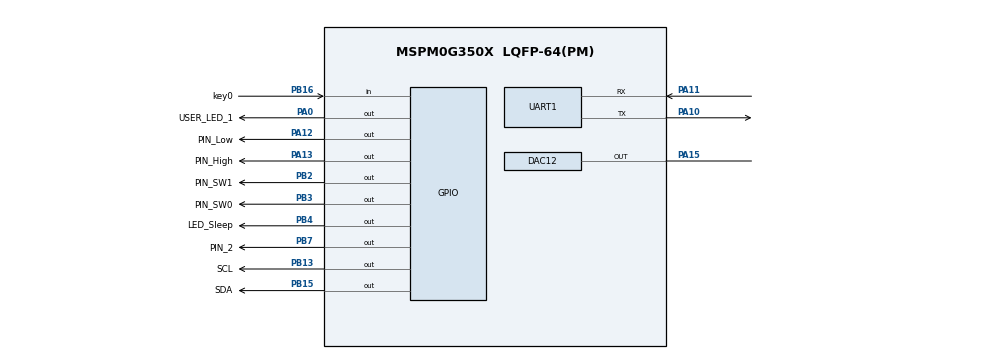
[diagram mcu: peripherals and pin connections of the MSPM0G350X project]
/**
 * @cliArgs --device "MSPM0G350X" --package "LQFP-64(PM)" --part "Default" --product "mspm0_sdk@1.30.00.03"
 * @versions {"tool":"1.20.0+3587"}
 */

/**
 * Import the modules used in this configuration.
 */
const ADC12         = scripting.addModule("/ti/driverlib/ADC12", {}, false);
const ADC121        = ADC12.addInstance();
const ADC122        = ADC12.addInstance();
const DAC12         = scripting.addModule("/ti/driverlib/DAC12");
const GPAMP         = scripting.addModule("/ti/driverlib/GPAMP", {}, false);
const GPAMP1        = GPAMP.addInstance();
const GPIO          = scripting.addModule("/ti/driverlib/GPIO", {}, false);
const GPIO1         = GPIO.addInstance();
const GPIO2         = GPIO.addInstance();
const GPIO3         = GPIO.addInstance();
const GPIO4         = GPIO.addInstance();
const GPIO5         = GPIO.addInstance();
const GPIO6         = GPIO.addInstance();
const MATHACL       = scripting.addModule("/ti/driverlib/MATHACL");
const OPA           = scripting.addModule("/ti/driverlib/OPA", {}, false);
const OPA1          = OPA.addInstance();
const OPA2          = OPA.addInstance();
const SYSCTL        = scripting.addModule("/ti/driverlib/SYSCTL");
const TIMER         = scripting.addModule("/ti/driverlib/TIMER", {}, false);
const TIMER1        = TIMER.addInstance();
const TIMER2        = TIMER.addInstance();
const UART          = scripting.addModule("/ti/driverlib/UART", {}, false);
const UART1         = UART.addInstance();
const UART2         = UART.addInstance();
const VREF          = scripting.addModule("/ti/driverlib/VREF");
const ProjectConfig = scripting.addModule("/ti/project_config/ProjectConfig");

/**
 * Write custom configuration values to the imported modules.
 */
const gate8  = system.clockTree["MFPCLKGATE"];
gate8.enable = true;

const multiplier2         = system.clockTree["PLL_QDIV"];
multiplier2.multiplyValue = 5;

ADC121.$name                 = "ADC12_0";
ADC121.adcMem0avgen          = true;
ADC121.hwNumerator           = "DL_ADC12_HW_AVG_NUM_ACC_16";
ADC121.powerDownMode         = "DL_ADC12_POWER_DOWN_MODE_MANUAL";
ADC121.samplingOperationMode = "sequence";
ADC121.endAdd                = 1;
ADC121.adcMem1avgen          = true;
ADC121.hwDenominator         = "DL_ADC12_HW_AVG_DEN_DIV_BY_16";
ADC121.sampCnt               = 2;
ADC121.repeatMode            = true;
ADC121.enabledDMATriggers    = ["DL_ADC12_DMA_MEM11_RESULT_LOADED","DL_ADC12_DMA_MEM1_RESULT_LOADED","DL_ADC12_DMA_MEM3_RESULT_LOADED","DL_ADC12_DMA_MEM5_RESULT_LOADED","DL_ADC12_DMA_MEM7_RESULT_LOADED","DL_ADC12_DMA_MEM9_RESULT_LOADED"];
ADC121.enabledInterrupts     = ["DL_ADC12_INTERRUPT_MEM1_RESULT_LOADED"];
ADC121.sampleTime0           = "62.5 ns";
ADC121.adcMem1chansel        = "DL_ADC12_INPUT_CHAN_13";
ADC121.adcMem0chansel        = "DL_ADC12_INPUT_CHAN_14";

ADC122.$name               = "ADC12_1";
ADC122.adcMem0chansel      = "DL_ADC12_INPUT_CHAN_2";
ADC122.enabledInterrupts   = ["DL_ADC12_INTERRUPT_MEM0_RESULT_LOADED"];
ADC122.adcMem0avgen        = true;
ADC122.hwNumerator         = "DL_ADC12_HW_AVG_NUM_ACC_16";
ADC122.hwDenominator       = "DL_ADC12_HW_AVG_DEN_DIV_BY_16";
ADC122.repeatMode          = true;
ADC122.sampleTime0         = "100us";
ADC122.adcPin2Config.$name = "ti_driverlib_gpio_GPIOPinGeneric8";

const Board = scripting.addModule("/ti/driverlib/Board", {}, false);

DAC12.dacFIFOEn                 = true;
DAC12.dacSampleTimerRate        = "1M";
DAC12.dacOutputPinEn            = true;
DAC12.dacConfigureDMA           = true;
DAC12.dacFIFOThresh             = "TWO_QTRS_EMPTY";
DAC12.dacAmplifier              = "ON";
DAC12.dacPosVREF                = "VEREFP";
DAC12.peripheral.OutPin.$assign = "PA15";
DAC12.OutPinConfig.$name        = "ti_driverlib_gpio_GPIOPinGeneric2";
DAC12.DMA_CHANNEL.$name         = "DMA_CH1";
DAC12.DMA_CHANNEL.srcLength     = "HALF_WORD";
DAC12.DMA_CHANNEL.dstLength     = "HALF_WORD";
DAC12.DMA_CHANNEL.addressMode   = "b2f";
DAC12.DMA_CHANNEL.transferMode  = "FULL_CH_REPEAT_SINGLE";

GPAMP1.$name                = "GPAMP_0";
GPAMP1.cfgPSELChannel       = "IN_POS";
GPAMP1.cfgNSELChannel       = "INTERNAL_OUTPUT";
GPAMP1.cfgChoppingMode      = "ADC_ASSISTED";
GPAMP1.InPosPinConfig.$name = "ti_driverlib_gpio_GPIOPinGeneric9";

GPIO1.$name                          = "GPIO_LEDS";
GPIO1.associatedPins.create(2);
GPIO1.associatedPins[0].$name        = "USER_LED_1";
GPIO1.associatedPins[0].assignedPort = "PORTA";
GPIO1.associatedPins[0].initialValue = "SET";
GPIO1.associatedPins[0].assignedPin  = "0";
GPIO1.associatedPins[0].pin.$assign  = "PA0";
GPIO1.associatedPins[1].$name        = "LED_Sleep";
GPIO1.associatedPins[1].initialValue = "SET";
GPIO1.associatedPins[1].pin.$assign  = "PB4";

GPIO2.$name                         = "GPIO_IIC";
GPIO2.port                          = "PORTB";
GPIO2.associatedPins.create(2);
GPIO2.associatedPins[0].$name       = "SCL";
GPIO2.associatedPins[0].pin.$assign = "PB13";
GPIO2.associatedPins[1].$name       = "SDA";
GPIO2.associatedPins[1].pin.$assign = "PB15";

GPIO3.$name                              = "GPIO_KEY";
GPIO3.associatedPins[0].direction        = "INPUT";
GPIO3.associatedPins[0].interruptEn      = true;
GPIO3.associatedPins[0].$name            = "key0";
GPIO3.associatedPins[0].polarity         = "RISE_FALL";
GPIO3.associatedPins[0].internalResistor = "PULL_UP";
GPIO3.associatedPins[0].pin.$assign      = "PB16";

GPIO4.$name                          = "GPIO_Relay";
GPIO4.associatedPins[0].$name        = "PIN_2";
GPIO4.associatedPins[0].initialValue = "SET";
GPIO4.associatedPins[0].pin.$assign  = "PB7";

GPIO5.$name                         = "GPIO_Measure";
GPIO5.associatedPins.create(2);
GPIO5.associatedPins[0].$name       = "PIN_High";
GPIO5.associatedPins[0].pin.$assign = "PA13";
GPIO5.associatedPins[1].$name       = "PIN_Low";
GPIO5.associatedPins[1].pin.$assign = "PA12";

GPIO6.$name                          = "GPIO_SW";
GPIO6.port                           = "PORTB";
GPIO6.associatedPins.create(2);
GPIO6.associatedPins[0].$name        = "PIN_SW1";
GPIO6.associatedPins[0].pin.$assign  = "PB2";
GPIO6.associatedPins[1].$name        = "PIN_SW0";
GPIO6.associatedPins[1].initialValue = "SET";
GPIO6.associatedPins[1].pin.$assign  = "PB3";

OPA1.$name                 = "OPA_0";
OPA1.cfg0PSELChannel       = "IN1_POS";
OPA1.cfg0NSELChannel       = "RTAP";
OPA1.advRRI                = true;
OPA1.advBW                 = "HIGH";
OPA1.cfg0Gain              = "N1_P2";
OPA1.cfg0Chop              = "ADC_AVERAGING";
OPA1.cfg0MSELChannel       = "IN1_NEG";
OPA1.peripheral.$assign    = "OPA0";
OPA1.In1PosPinConfig.$name = "ti_driverlib_gpio_GPIOPinGeneric4";
OPA1.In1NegPinConfig.$name = "ti_driverlib_gpio_GPIOPinGeneric11";

OPA2.$name                 = "OPA_1";
OPA2.cfg0PSELChannel       = "IN1_POS";
OPA2.cfg0NSELChannel       = "RTAP";
OPA2.advBW                 = "HIGH";
OPA2.advRRI                = true;
OPA2.cfg0MSELChannel       = "GND";
OPA2.cfg0OutputPin         = "ENABLED";
OPA2.cfg0Gain              = "N1_P2";
OPA2.cfg0Chop              = "STANDARD";
OPA2.In1PosPinConfig.$name = "ti_driverlib_gpio_GPIOPinGeneric7";
OPA2.OutPinConfig.$name    = "ti_driverlib_gpio_GPIOPinGeneric5";

SYSCTL.clockTreeEn           = true;
SYSCTL.forceDefaultClkConfig = true;

TIMER1.$name              = "TIMER_0";
TIMER1.timerClkPrescale   = 256;
TIMER1.interrupts         = ["ZERO"];
TIMER1.timerPeriod        = "30s";
TIMER1.timerClkSrc        = "LFCLK";
TIMER1.peripheral.$assign = "TIMG0";

TIMER2.$name              = "TIMER_1";
TIMER2.interrupts         = ["ZERO"];
TIMER2.timerClkDiv        = 2;
TIMER2.timerClkPrescale   = 32;
TIMER2.timerPeriod        = "100 ms";
TIMER2.timerMode          = "PERIODIC";
TIMER2.peripheral.$assign = "TIMG8";

UART1.$name                             = "UART_0";
UART1.enableFIFO                        = true;
UART1.rxFifoThreshold                   = "DL_UART_RX_FIFO_LEVEL_ONE_ENTRY";
UART1.txFifoThreshold                   = "DL_UART_TX_FIFO_LEVEL_ONE_ENTRY";
UART1.enabledDMATXTriggers              = "DL_UART_DMA_INTERRUPT_TX";
UART1.targetBaudRate                    = 115200;
UART1.enabledInterrupts                 = ["DMA_DONE_RX","DMA_DONE_TX","EOT_DONE"];
UART1.enabledDMARXTriggers              = "DL_UART_DMA_INTERRUPT_RX";
UART1.peripheral.$assign                = "UART0";
UART1.peripheral.rxPin.$assign          = "PA11";
UART1.peripheral.txPin.$assign          = "PA10";
UART1.txPinConfig.$name                 = "ti_driverlib_gpio_GPIOPinGeneric0";
UART1.rxPinConfig.$name                 = "ti_driverlib_gpio_GPIOPinGeneric1";
UART1.DMA_CHANNEL_TX.$name              = "DMA_CH0";
UART1.DMA_CHANNEL_TX.addressMode        = "b2f";
UART1.DMA_CHANNEL_TX.dstLength          = "BYTE";
UART1.DMA_CHANNEL_TX.srcLength          = "BYTE";
UART1.DMA_CHANNEL_TX.peripheral.$assign = "DMA_CH0";
UART1.DMA_CHANNEL_RX.$name              = "DMA_CH2";
UART1.DMA_CHANNEL_RX.srcLength          = "BYTE";
UART1.DMA_CHANNEL_RX.dstLength          = "BYTE";
UART1.DMA_CHANNEL_RX.addressMode        = "f2b";

UART2.$name                  = "UART_1";
UART2.enableFIFO             = true;
UART2.txFifoThreshold        = "DL_UART_TX_FIFO_LEVEL_3_4_EMPTY";
UART2.enableDMATX            = false;
UART2.enableDMARX            = false;
UART2.rxFifoThreshold        = "DL_UART_RX_FIFO_LEVEL_ONE_ENTRY";
UART2.targetBaudRate         = 115200;
UART2.enableInternalLoopback = true;
UART2.txPinConfig.$name      = "ti_driverlib_gpio_GPIOPinGeneric3";
UART2.rxPinConfig.$name      = "ti_driverlib_gpio_GPIOPinGeneric10";

VREF.vrefPosPinConfig.$name = "ti_driverlib_gpio_GPIOPinGeneric6";

ProjectConfig.genLibIQ        = true;
ProjectConfig.genLibIQVersion = "MATHACL";

/**
 * Pinmux solution for unlocked pins/peripherals. This ensures that minor changes to the automatic solver in a future
 * version of the tool will not impact the pinmux you originally saw.  These lines can be completely deleted in order to
 * re-solve from scratch.
 */
ADC121.peripheral.$suggestSolution               = "ADC0";
ADC122.peripheral.$suggestSolution               = "ADC1";
ADC122.peripheral.adcPin2.$suggestSolution       = "PA17";
Board.peripheral.$suggestSolution                = "DEBUGSS";
Board.peripheral.swclkPin.$suggestSolution       = "PA20";
Board.peripheral.swdioPin.$suggestSolution       = "PA19";
DAC12.peripheral.$suggestSolution                = "DAC0";
DAC12.DMA_CHANNEL.peripheral.$suggestSolution    = "DMA_CH2";
GPAMP1.peripheral.$suggestSolution               = "GPAMP";
GPAMP1.peripheral.InPosPin.$suggestSolution      = "PA26";
OPA1.peripheral.In1PosPin.$suggestSolution       = "PA25";
OPA1.peripheral.In1NegPin.$suggestSolution       = "PA24";
OPA2.peripheral.$suggestSolution                 = "OPA1";
OPA2.peripheral.In1PosPin.$suggestSolution       = "PA18";
OPA2.peripheral.OutPin.$suggestSolution          = "PA16";
UART1.DMA_CHANNEL_RX.peripheral.$suggestSolution = "DMA_CH1";
UART2.peripheral.$suggestSolution                = "UART1";
UART2.peripheral.rxPin.$suggestSolution          = "PA9";
UART2.peripheral.txPin.$suggestSolution          = "PA8";
VREF.peripheral.$suggestSolution                 = "VREF";
VREF.peripheral.vrefPosPin.$suggestSolution      = "PA23";
